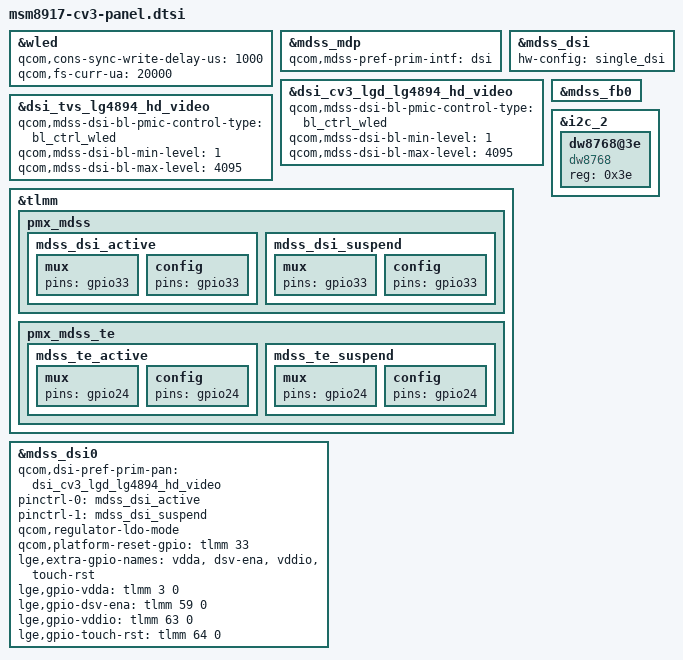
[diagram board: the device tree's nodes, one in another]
/*
 * Copyright (c) 2016, The Linux Foundation. All rights reserved.
 *
 * This program is free software; you can redistribute it and/or modify
 * it under the terms of the GNU General Public License version 2 and
 * only version 2 as published by the Free Software Foundation.
 *
 * This program is distributed in the hope that it will be useful,
 * but WITHOUT ANY WARRANTY; without even the implied warranty of
 * MERCHANTABILITY or FITNESS FOR A PARTICULAR PURPOSE.  See the
 * GNU General Public License for more details.
 */

#include "../dsi-panel-cv3-lgd-lg4894-hd-video.dtsi"
#include "../dsi-panel-cv3-tovis-lg4894-hd-video.dtsi"
#include "../ext_dsv_cv3_dw8768.dtsi"


&wled {
	qcom,cons-sync-write-delay-us = <1000>;
};

&mdss_mdp {
	qcom,mdss-pref-prim-intf = "dsi";
};

&mdss_dsi {
	hw-config = "single_dsi";
};


&dsi_cv3_lgd_lg4894_hd_video {
	qcom,mdss-dsi-bl-pmic-control-type = "bl_ctrl_wled";
	qcom,mdss-dsi-bl-min-level = <1>;
	qcom,mdss-dsi-bl-max-level = <4095>;
};

&dsi_tvs_lg4894_hd_video {
	qcom,mdss-dsi-bl-pmic-control-type = "bl_ctrl_wled";
	qcom,mdss-dsi-bl-min-level = <1>;
	qcom,mdss-dsi-bl-max-level = <4095>;
};

&tlmm {
	pmx_mdss {
		mdss_dsi_active: mdss_dsi_active {
			mux {
				pins = "gpio33";
			};

			config {
				pins = "gpio33";
			};
		};

		mdss_dsi_suspend: mdss_dsi_suspend {
			mux {
				pins = "gpio33";
			};

			config {
				pins = "gpio33";
			};
		};
	};

	pmx_mdss_te {
		mdss_te_active: mdss_te_active {
			mux {
				pins = "gpio24";
			};

			config {
				pins = "gpio24";
			};
		};

		mdss_te_suspend: mdss_te_suspend {
			mux {
				pins = "gpio24";
			};

			config {
				pins = "gpio24";
			};
		};
	};
};

&mdss_dsi0 {
	qcom,dsi-pref-prim-pan = <&dsi_cv3_lgd_lg4894_hd_video>;
	pinctrl-names = "mdss_default", "mdss_sleep";
	pinctrl-0 = <&mdss_dsi_active>;
	pinctrl-1 = <&mdss_dsi_suspend>;
	qcom,regulator-ldo-mode;
	qcom,platform-reset-gpio = <&tlmm 33 0>;

	lge,extra-gpio-names = "vdda", "dsv-ena","vddio", "touch-rst";

	lge,gpio-vdda = <&tlmm 3 0>;
	lge,gpio-dsv-ena = <&tlmm 59 0>;
	lge,gpio-vddio = <&tlmm 63 0>;
	lge,gpio-touch-rst = <&tlmm 64 0>;

	/delete-property/ vdd-supply;
};

&mdss_fb0 {
	/delete-property/ qcom,mdss-fb-splash-logo-enabled;
};

&i2c_2 {
	dw8768@3e {
		status = "ok";
		compatible = "dw8768";
		reg = <0x3e>;
	};
};

&wled {
	qcom,fs-curr-ua = <20000>;
	/*qcom,led-strings-list = [00];*/
};
